# CORE_TA_GPTIMER11 register map
Vendor: Texas Instruments
Peripheral module from a debugger description file (folder omap36xx).
Registers are 32-bit, read-only, reset 0x0 unless marked. A register's access mark holds for its fields unless they carry their own. Offsets are as the file gives them; lines under a group give offsets from that group; [hi:lo] are bit positions; {n}, {i} and the like mark numbered series; 'fields as' and 'values as' point back to an identical list; <NAME> marks a mode.

## CORE_TA_GPTIMER11
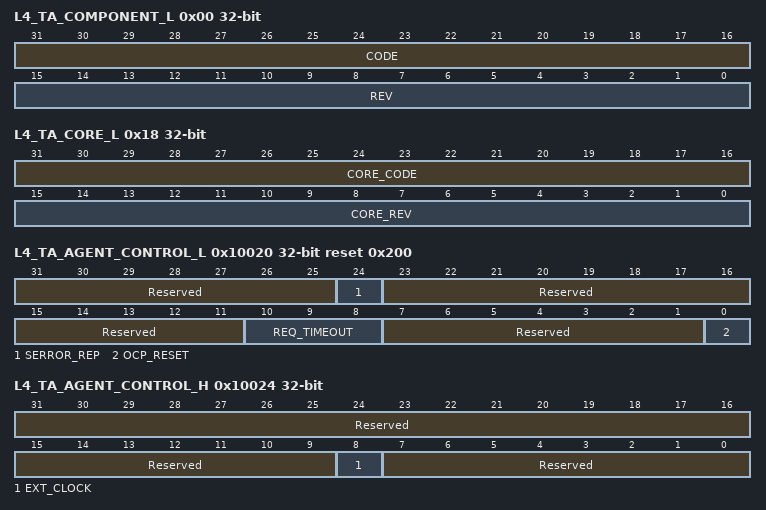
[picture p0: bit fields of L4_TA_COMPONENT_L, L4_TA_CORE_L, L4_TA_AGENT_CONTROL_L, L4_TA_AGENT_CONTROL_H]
0x00 L4_TA_COMPONENT_L reset not defined — Contains a component code and revision.
  [31:16] CODE — Interconnect code.
  [15:0] REV — Component revision code.
0x04 L4_TA_COMPONENT_H — Contains a component code and revision.
  [31:0] Reserved — Read returns 0
0x18 L4_TA_CORE_L reset not defined — Contains a component code and revision.
  [31:16] CORE_CODE — Interconnect core code
  [15:0] CORE_REV — Component revision code code
0x1C L4_TA_CORE_H (reset mask 0xFFFF0000) — Contains a component code and revision.
  [15:0] VENDOR_CODE — Vendor revision core code
0x10020 L4_TA_AGENT_CONTROL_L access not given reset 0x200 (reset mask 0xFF0007FF) — Enable error reporting
  [31:25] Reserved ro — Read returns 0.
  [24] SERROR_REP ro — Enable logging of error
  [23:11] Reserved — Read returns 0.
  [10:8] REQ_TIMEOUT rw — Timeout Bound. Values are:0 - No timeout1 - 1x base cycles . 2 - 4x base cycles . 3 - 16x base cycles . 4 - 64x base cycles .
  [7:1] Reserved ro — Read returns 0.
  [0] OCP_RESET rw — The OCP_RESET field controls the OCP reset signal to the attached core. Setting this bit clears any pending transfers and resets the OCP interface. The bit must be cleared to de-assert the OCP reset signal.When the software reset feature is available on a target agent, the target agent OCP must also have a reset signal directed to the target core.
0x10024 L4_TA_AGENT_CONTROL_H — Enable clock power management
  [31:9] Reserved — Read returns 0.
  [8] EXT_CLOCK — When set to 1, the ext_clk_off_i signal on a target agent indicates when the target agent should shut off.
  [7:0] Reserved — Read returns 0.
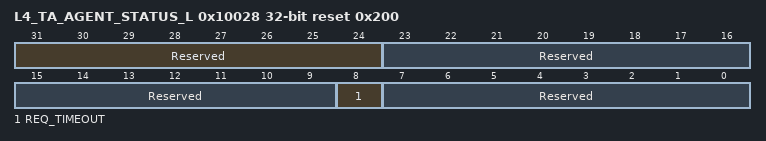
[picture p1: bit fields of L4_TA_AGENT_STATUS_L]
0x10028 L4_TA_AGENT_STATUS_L access not given reset 0x200 — Error reporting
  [31:24] Reserved ro — Read returns 0.
  [23:9] Reserved ro — Read returns 0.
  [8] REQ_TIMEOUT — 0x0: No request timeout0x1: A request timeout has occurred (access R 1toCLR)
  [7:0] Reserved ro — Read returns 0.
0x1002C L4_TA_AGENT_STATUS_H — Error reporting
  [31:0] Reserved — Read returns 0
